# M3U6 register map
File version: 2.0.2.11
Registers are 32-bit, read-write, reset 0x0 unless marked. A register's access mark holds for its fields unless they carry their own. Offsets are from the block's base; [hi:lo] are bit positions; {n}, {i} and the like mark numbered series.

## PC — General Purpose Input_Output Port (PC)
Base 0x40000080
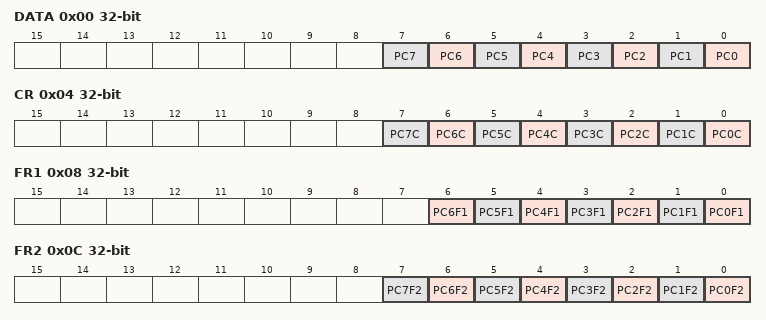
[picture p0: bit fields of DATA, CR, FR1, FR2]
0x00 DATA — PC Data Register
  [n] PC{n} (n=0..7)
0x04 CR — PC Control Register
  [n] PC{n}C (n=0..7)
0x08 FR1 — PC Function Register 1
  [n] PC{n}F1 (n=0..6)
0x0C FR2 — PC Function Register 2
  [n] PC{n}F2 (n=0..7)
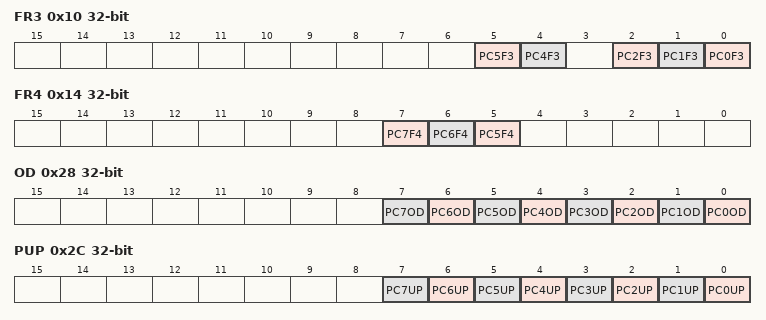
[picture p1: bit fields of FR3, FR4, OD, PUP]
0x10 FR3 — PC Function Register 3
  [5] PC5F3, [4] PC4F3, [2] PC2F3, [1] PC1F3, [0] PC0F3
0x14 FR4 — PC Function Register 4
  [7] PC7F4, [6] PC6F4, [5] PC5F4
0x18 FR5 — PC Function Register 5
  [5] PC5F5
0x28 OD — PC Open Drain Control Register
  [n] PC{n}OD (n=0..7)
0x2C PUP — PC Pull-Up Control Register
  [n] PC{n}UP (n=0..7)
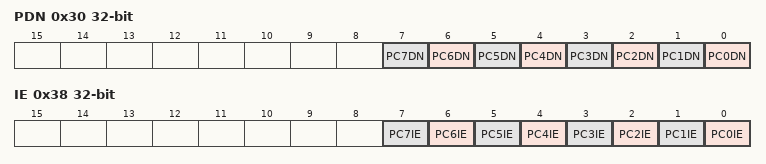
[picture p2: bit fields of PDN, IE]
0x30 PDN — PC Pull-Down Control Register
  [n] PC{n}DN (n=0..7)
0x38 IE — PC Input Enable Control Register
  [n] PC{n}IE (n=0..7)

## PD — General Purpose Input_Output Port (PD)
Base 0x400000C0
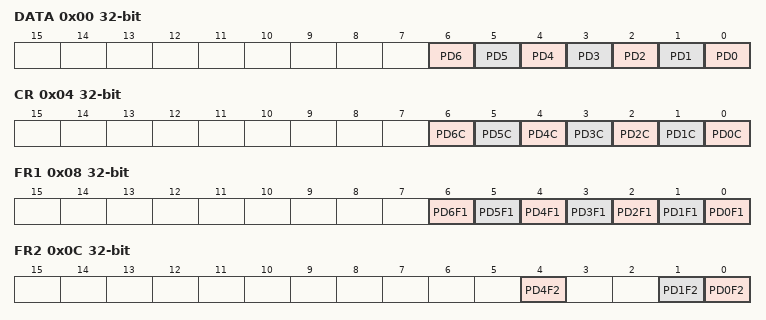
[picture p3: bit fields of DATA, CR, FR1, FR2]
0x00 DATA — PD Data Register
  [n] PD{n} (n=0..6)
0x04 CR — PD Control Register
  [n] PD{n}C (n=0..6)
0x08 FR1 — PD Function Register 1
  [n] PD{n}F1 (n=0..6)
0x0C FR2 — PD Function Register 2
  [4] PD4F2, [1] PD1F2, [0] PD0F2
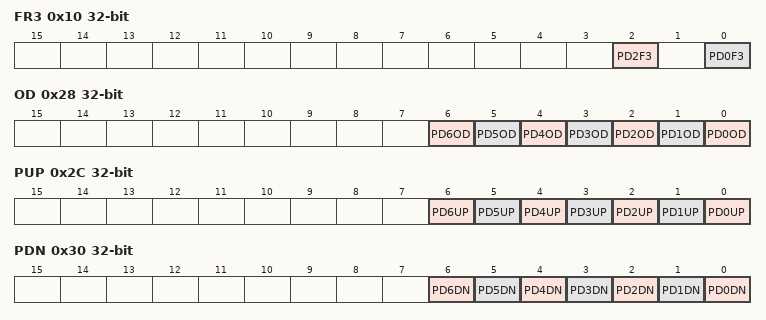
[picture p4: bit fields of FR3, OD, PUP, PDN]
0x10 FR3 — PD Function Register 3
  [2] PD2F3, [0] PD0F3
0x28 OD — PD Open Drain Control Register
  [n] PD{n}OD (n=0..6)
0x2C PUP — PD Pull-Up Control Register
  [n] PD{n}UP (n=0..6)
0x30 PDN — PD Pull-Down Control Register
  [n] PD{n}DN (n=0..6)
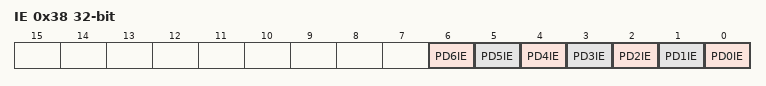
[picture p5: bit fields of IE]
0x38 IE — PD Input Enable Control Register
  [n] PD{n}IE (n=0..6)

## PE — General Purpose Input_Output Port (PE)
Base 0x40000100
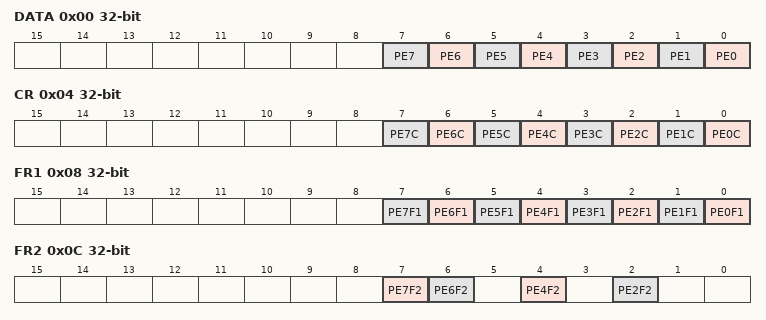
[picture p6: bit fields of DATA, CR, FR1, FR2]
0x00 DATA — PE Data Register
  [n] PE{n} (n=0..7)
0x04 CR — PE Control Register
  [n] PE{n}C (n=0..7)
0x08 FR1 — PE Function Register 1
  [n] PE{n}F1 (n=0..7)
0x0C FR2 — PE Function Register 2
  [7] PE7F2, [6] PE6F2, [4] PE4F2, [2] PE2F2
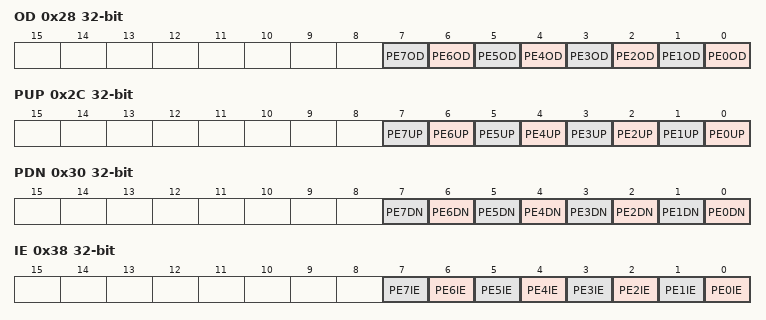
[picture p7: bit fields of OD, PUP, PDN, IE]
0x28 OD — PE Open Drain Control Register
  [n] PE{n}OD (n=0..7)
0x2C PUP — PE Pull-Up Control Register
  [n] PE{n}UP (n=0..7)
0x30 PDN — PE Pull-Down Control Register
  [n] PE{n}DN (n=0..7)
0x38 IE — PE Input Enable Control Register
  [n] PE{n}IE (n=0..7)

## PF — General Purpose Input_Output Port (PF)
Base 0x40000140
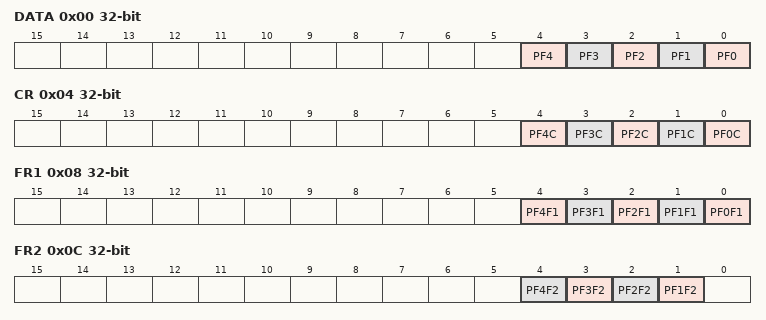
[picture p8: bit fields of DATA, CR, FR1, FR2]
0x00 DATA — PF Data Register
  [n] PF{n} (n=0..4)
0x04 CR — PF Control Register
  [n] PF{n}C (n=0..4)
0x08 FR1 — PF Function Register 1
  [n] PF{n}F1 (n=0..4)
0x0C FR2 — PF Function Register 2
  [n] PF{n}F2 (n=1..4)
0x10 FR3 — PF Function Register 3
  [2] PF2F3
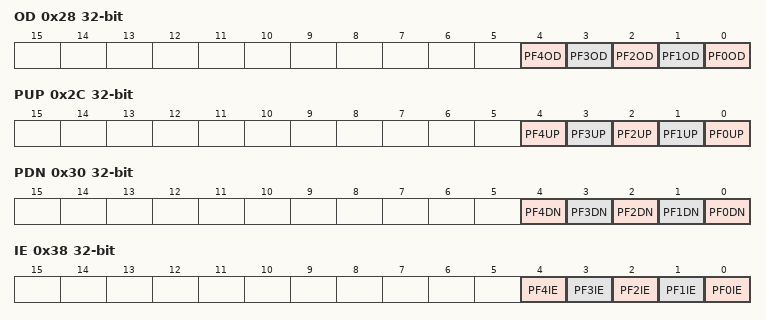
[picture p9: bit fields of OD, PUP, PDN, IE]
0x28 OD — PF Open Drain Control Register
  [n] PF{n}OD (n=0..4)
0x2C PUP — PF Pull-Up Control Register
  [n] PF{n}UP (n=0..4)
0x30 PDN — PF Pull-Down Control Register
  [n] PF{n}DN (n=0..4)
0x38 IE — PF Input Enable Control Register
  [n] PF{n}IE (n=0..4)

## PG — General Purpose Input_Output Port (PG)
Base 0x40000180
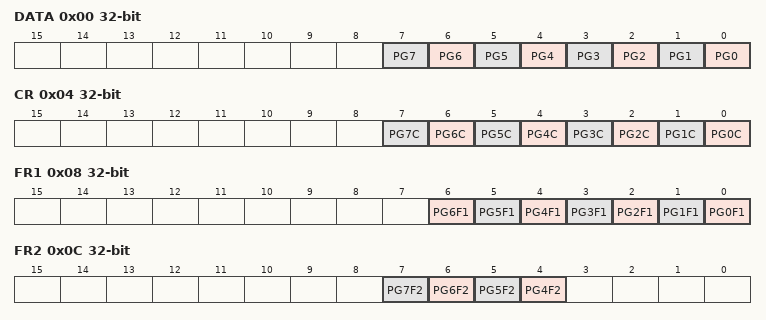
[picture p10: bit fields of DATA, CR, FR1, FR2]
0x00 DATA — PG Data Register
  [n] PG{n} (n=0..7)
0x04 CR — PG Control Register
  [n] PG{n}C (n=0..7)
0x08 FR1 — PG Function Register 1
  [n] PG{n}F1 (n=0..6)
0x0C FR2 — PG Function Register 2
  [n] PG{n}F2 (n=4..7)
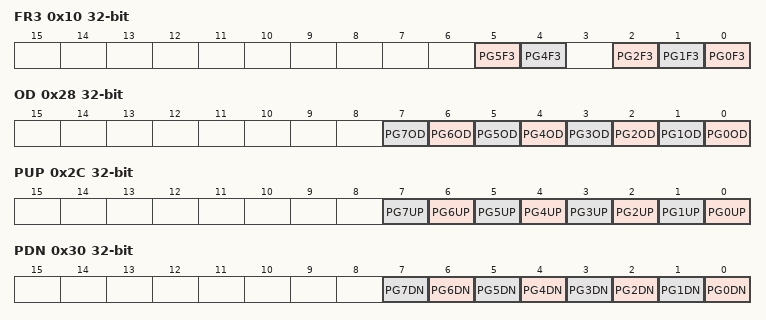
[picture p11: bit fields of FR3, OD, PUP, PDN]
0x10 FR3 — PG Function Register 3
  [5] PG5F3, [4] PG4F3, [2] PG2F3, [1] PG1F3, [0] PG0F3
0x28 OD — PG Open Drain Control Register
  [n] PG{n}OD (n=0..7)
0x2C PUP — PG Pull-Up Control Register
  [n] PG{n}UP (n=0..7)
0x30 PDN — PG Pull-Down Control Register
  [n] PG{n}DN (n=0..7)
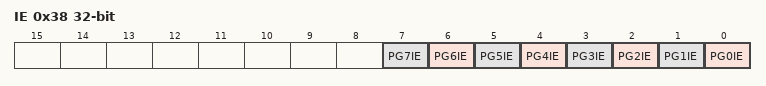
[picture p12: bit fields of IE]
0x38 IE — PG Input Enable Control Register
  [n] PG{n}IE (n=0..7)

## PH — General Purpose Input_Output Port (PH)
Base 0x400001C0
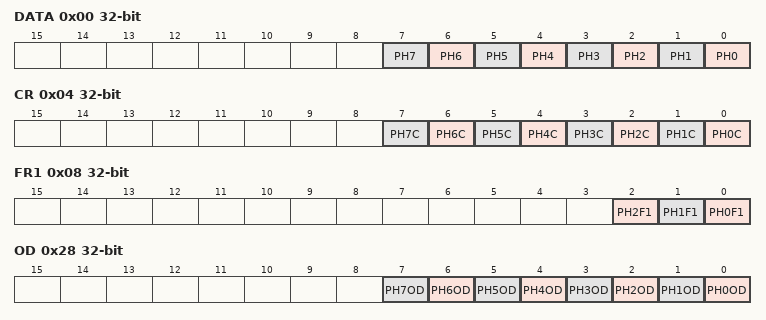
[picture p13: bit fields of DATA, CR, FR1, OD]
0x00 DATA — PH Data Register
  [n] PH{n} (n=0..7)
0x04 CR — PH Control Register
  [n] PH{n}C (n=0..7)
0x08 FR1 — PH Function Register 1
  [2] PH2F1, [1] PH1F1, [0] PH0F1
0x28 OD — PH Open Drain Control Register
  [n] PH{n}OD (n=0..7)
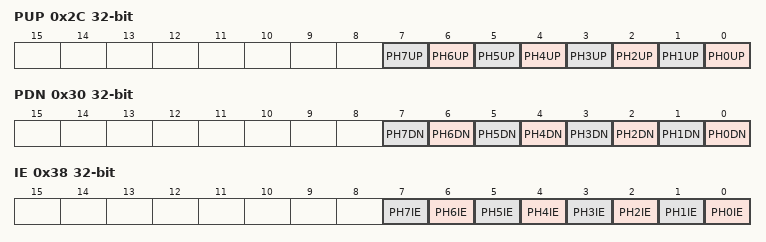
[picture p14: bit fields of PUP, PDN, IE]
0x2C PUP — PH Pull-Up Control Register
  [n] PH{n}UP (n=0..7)
0x30 PDN — PH Pull-Down Control Register
  [n] PH{n}DN (n=0..7)
0x38 IE — PH Input Enable Control Register
  [n] PH{n}IE (n=0..7)

## PI — General Purpose Input_Output Port (PI)
Base 0x40000200
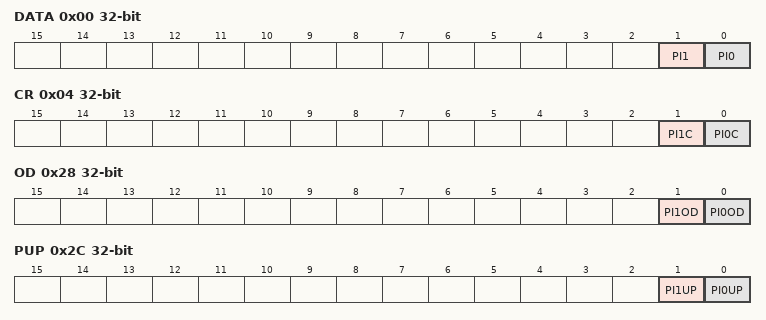
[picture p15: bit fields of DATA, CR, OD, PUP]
0x00 DATA — PI Data Register
  [1] PI1, [0] PI0
0x04 CR — PI Control Register
  [1] PI1C, [0] PI0C
0x28 OD — PI Open Drain Control Register
  [1] PI1OD, [0] PI0OD
0x2C PUP — PI Pull-Up Control Register
  [1] PI1UP, [0] PI0UP
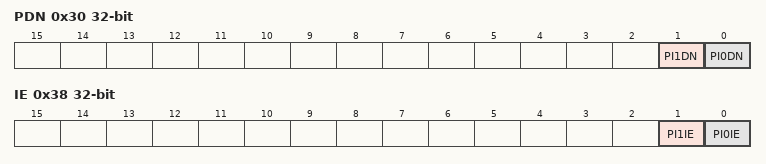
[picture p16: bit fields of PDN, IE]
0x30 PDN — PI Pull-Down Control Register
  [1] PI1DN, [0] PI0DN
0x38 IE — PI Input Enable Control Register
  [1] PI1IE, [0] PI0IE
